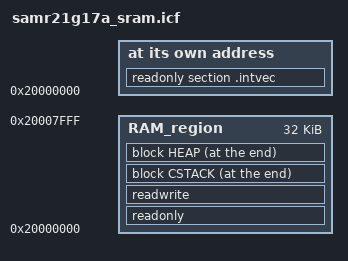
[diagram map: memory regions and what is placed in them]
/**
 * \file
 *
 * \brief Linker script for running in internal SRAM on the SAMR21G17A
 *
 * Copyright (c) 2018 Microchip Technology Inc. and its subsidiaries. 
 *
 * \asf_license_start
 *
 * \page License
 *
 * Subject to your compliance with these terms, you may use Microchip
 * software and any derivatives exclusively with Microchip products. 
 * It is your responsibility to comply with third party license terms applicable 
 * to your use of third party software (including open source software) that 
 * may accompany Microchip software.
 *
 * THIS SOFTWARE IS SUPPLIED BY MICROCHIP "AS IS".  NO WARRANTIES, 
 * WHETHER EXPRESS, IMPLIED OR STATUTORY, APPLY TO THIS SOFTWARE, 
 * INCLUDING ANY IMPLIED WARRANTIES OF NON-INFRINGEMENT, MERCHANTABILITY, 
 * AND FITNESS FOR A PARTICULAR PURPOSE. IN NO EVENT WILL MICROCHIP BE 
 * LIABLE FOR ANY INDIRECT, SPECIAL, PUNITIVE, INCIDENTAL OR CONSEQUENTIAL 
 * LOSS, DAMAGE, COST OR EXPENSE OF ANY KIND WHATSOEVER RELATED TO THE 
 * SOFTWARE, HOWEVER CAUSED, EVEN IF MICROCHIP HAS BEEN ADVISED OF THE 
 * POSSIBILITY OR THE DAMAGES ARE FORESEEABLE.  TO THE FULLEST EXTENT 
 * ALLOWED BY LAW, MICROCHIP'S TOTAL LIABILITY ON ALL CLAIMS IN ANY WAY 
 * RELATED TO THIS SOFTWARE WILL NOT EXCEED THE AMOUNT OF FEES, IF ANY, 
 * THAT YOU HAVE PAID DIRECTLY TO MICROCHIP FOR THIS SOFTWARE.
 *
 * \asf_license_stop
 *
 */
/*
 * Support and FAQ: visit <a href="https://www.microchip.com/support/">Microchip Support</a>
*/

/*###ICF### Section handled by ICF editor, don't touch! ****/
/*-Editor annotation file-*/
/* IcfEditorFile="$TOOLKIT_DIR$\config\ide\IcfEditor\cortex_v1_0.xml" */
/*-Specials-*/
define symbol __ICFEDIT_intvec_start__        = 0x20000000;
/*-Memory Regions-*/
define symbol __ICFEDIT_region_RAM_start__    = 0x20000000;
define symbol __ICFEDIT_region_RAM_end__      = 0x20007FFF;
/*-Sizes-*/
if (!isdefinedsymbol(__ICFEDIT_size_cstack__)) {
  define symbol __ICFEDIT_size_cstack__    = 0x2000;
}
if (!isdefinedsymbol(__ICFEDIT_size_heap__)) {
  define symbol __ICFEDIT_size_heap__      = 0x0;
}
/**** End of ICF editor section. ###ICF###*/

define memory mem with size = 4G;
define region RAM_region    = mem:[from __ICFEDIT_region_RAM_start__ to __ICFEDIT_region_RAM_end__];

define block CSTACK with alignment = 8, size = __ICFEDIT_size_cstack__ { };
define block HEAP   with alignment = 8, size = __ICFEDIT_size_heap__   { };

initialize by copy with packing=none { readwrite };
do not initialize  { section .noinit };

place at address mem:__ICFEDIT_intvec_start__ { readonly section .intvec };
place in RAM_region                           { readonly };
place in RAM_region                           { readwrite };
place at end of RAM_region                    { block CSTACK, block HEAP };
